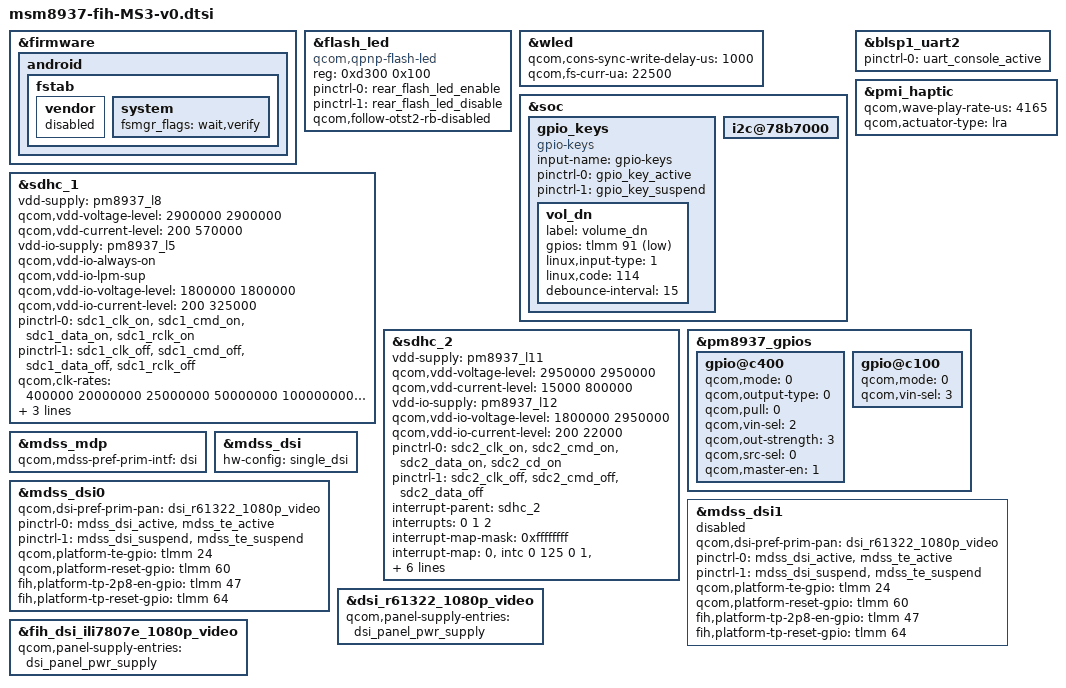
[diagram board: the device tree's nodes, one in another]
/*
 * Copyright (c) 2015-2016, The Linux Foundation. All rights reserved.
 *
 * This program is free software; you can redistribute it and/or modify
 * it under the terms of the GNU General Public License version 2 and
 * only version 2 as published by the Free Software Foundation.
 *
 * This program is distributed in the hope that it will be useful,
 * but WITHOUT ANY WARRANTY; without even the implied warranty of
 * MERCHANTABILITY or FITNESS FOR A PARTICULAR PURPOSE.  See the
 * GNU General Public License for more details.
 */

//#include "msm8937-pinctrl.dtsi"
#include "msm8937-pinctrl-MS3.dtsi"
#include "components/camera/msm8937-camera-sensor-ms3_pre-evt.dtsi"

/*LED*/
#include "components/fih/msm8937-pmi8950-led-gpio1.dtsi"

/* Reserved memory hole */
#include "components/memmap/memmap_8937_v0.dtsi"

/* Pstore:last kmsg */
#include "components/memmap/msm8937-memory-pstore.dtsi"

/* Disable Vendor partition */
&firmware {
  android {
    fstab {
      vendor {
        status = "disabled";
      };
      system {
        fsmgr_flags = "wait,verify";
        status = "ok";
      };
    };
  };
};

&flash_led {
	compatible = "qcom,qpnp-flash-led";
	reg = <0xd300 0x100>;
	pinctrl-names = "flash_led_enable","flash_led_disable";
	pinctrl-0 = <&rear_flash_led_enable>;
	pinctrl-1 = <&rear_flash_led_disable>;
	qcom,follow-otst2-rb-disabled;
};

&wled {
	qcom,cons-sync-write-delay-us = <1000>;
	qcom,fs-curr-ua = <22500>;
};

&soc {

  /include/ "components/fih/common_info_msm8976_v1.dtsi"

  /* FihtdcCode@AlanHZChang, Add for hall sensor */
  /include/ "components/hallsensor/hallsensor_v0.dtsi"

  /*Win Add for FPC fingerprint */
  /include/ "components/fingerprint/fingerprint_fpc_v0.dtsi"

	gpio_keys {
		compatible = "gpio-keys";
		input-name = "gpio-keys";
		pinctrl-names = "tlmm_gpio_key_active","tlmm_gpio_key_suspend";
		pinctrl-0 = <&gpio_key_active>;
		pinctrl-1 = <&gpio_key_suspend>;

		vol_dn {
			label = "volume_dn";
			gpios = <&tlmm 91 0x1>;
			linux,input-type = <1>;
			linux,code = <114>;
			debounce-interval = <15>;
		};
	};

	i2c@78b7000 {
	  status = "ok";
	  #include "components/touch/touch_focal_v0.dtsi"
	};
};

&blsp1_uart2 {
	status = "ok";
	pinctrl-names = "default";
	pinctrl-0 = <&uart_console_active>;
};

&pmi_haptic{
	qcom,wave-play-rate-us = <4165>;
	qcom,actuator-type = "lra";
};



&sdhc_1 {
	/* device core power supply */
	vdd-supply = <&pm8937_l8>;
	qcom,vdd-voltage-level = <2900000 2900000>;
	qcom,vdd-current-level = <200 570000>;

	/* device communication power supply */
	vdd-io-supply = <&pm8937_l5>;
	qcom,vdd-io-always-on;
	qcom,vdd-io-lpm-sup;
	qcom,vdd-io-voltage-level = <1800000 1800000>;
	qcom,vdd-io-current-level = <200 325000>;

	pinctrl-names = "active", "sleep";
	pinctrl-0 = <&sdc1_clk_on &sdc1_cmd_on &sdc1_data_on &sdc1_rclk_on>;
	pinctrl-1 = <&sdc1_clk_off &sdc1_cmd_off &sdc1_data_off &sdc1_rclk_off>;

	qcom,clk-rates = <400000 20000000 25000000 50000000 100000000 192000000
								384000000>;
	qcom,nonremovable;
	qcom,bus-speed-mode = "HS400_1p8v", "HS200_1p8v", "DDR_1p8v";

	status = "ok";
};

&sdhc_2 {
	/* device core power supply */
	vdd-supply = <&pm8937_l11>;
	qcom,vdd-voltage-level = <2950000 2950000>;
	qcom,vdd-current-level = <15000 800000>;

	/* device communication power supply */
	vdd-io-supply = <&pm8937_l12>;
	qcom,vdd-io-voltage-level = <1800000 2950000>;
	qcom,vdd-io-current-level = <200 22000>;

	pinctrl-names = "active", "sleep";
	pinctrl-0 = <&sdc2_clk_on &sdc2_cmd_on &sdc2_data_on &sdc2_cd_on>;
	pinctrl-1 = <&sdc2_clk_off &sdc2_cmd_off &sdc2_data_off>;

	#address-cells = <0>;
	interrupt-parent = <&sdhc_2>;
	interrupts = <0 1 2>;
	#interrupt-cells = <1>;
	interrupt-map-mask = <0xffffffff>;
	interrupt-map = <0 &intc 0 125 0
		1 &intc 0 221 0
		2 &tlmm 67 0>;
	interrupt-names = "hc_irq", "pwr_irq", "status_irq";
	cd-gpios = <&tlmm 67 0x0>;

	qcom,clk-rates = <400000 20000000 25000000 50000000 100000000
								200000000>;
	qcom,bus-speed-mode = "SDR12", "SDR25", "SDR50", "DDR50", "SDR104";

	status = "ok";
};

&pm8937_gpios {
	gpio@c400 {
		qcom,mode = <0>;
		qcom,output-type = <0>;
		qcom,pull = <0>;
		qcom,vin-sel = <2>;
		qcom,out-strength = <3>;
		qcom,src-sel = <0>;
		qcom,master-en = <1>;
		status = "okay";
	};
};

#include "msm8937-mdss-panels.dtsi"

&mdss_mdp {
	qcom,mdss-pref-prim-intf = "dsi";
};

&mdss_dsi {
	hw-config = "single_dsi";
};

&mdss_dsi0 {
	qcom,dsi-pref-prim-pan = <&dsi_r61322_1080p_video>;
	pinctrl-names = "mdss_default", "mdss_sleep";
	pinctrl-0 = <&mdss_dsi_active &mdss_te_active>;
	pinctrl-1 = <&mdss_dsi_suspend &mdss_te_suspend>;

	qcom,platform-te-gpio = <&tlmm 24 0>;
/*	qcom,platform-enable-gpio = <&tlmm 99 0>;*/
	qcom,platform-reset-gpio = <&tlmm 60 0>;
/*	qcom,platform-bklight-en-gpio = <&tlmm 98 0>;*/
	fih,platform-tp-2p8-en-gpio = <&tlmm 47 0>;
	fih,platform-tp-reset-gpio = <&tlmm 64 0>;
};

&mdss_dsi1 {
	status = "disabled";
	qcom,dsi-pref-prim-pan = <&dsi_r61322_1080p_video>;
	pinctrl-names = "mdss_default", "mdss_sleep";
	pinctrl-0 = <&mdss_dsi_active &mdss_te_active>;
	pinctrl-1 = <&mdss_dsi_suspend &mdss_te_suspend>;

	qcom,platform-te-gpio = <&tlmm 24 0>;
/*	qcom,platform-enable-gpio = <&tlmm 99 0>;*/
	qcom,platform-reset-gpio = <&tlmm 60 0>;
/*	qcom,platform-bklight-en-gpio = <&tlmm 98 0>;*/
	fih,platform-tp-2p8-en-gpio = <&tlmm 47 0>;
	fih,platform-tp-reset-gpio = <&tlmm 64 0>;
};

&dsi_r61322_1080p_video {
	qcom,panel-supply-entries = <&dsi_panel_pwr_supply>;
};

&fih_dsi_ili7807e_1080p_video {
	qcom,panel-supply-entries = <&dsi_panel_pwr_supply>;
};

/* PM8937 GPIO configuration */
&pm8937_gpios {
	gpio@c100 {
		qcom,mode = <0>;
		qcom,vin-sel = <3>;
		status = "okay";
	};
};
